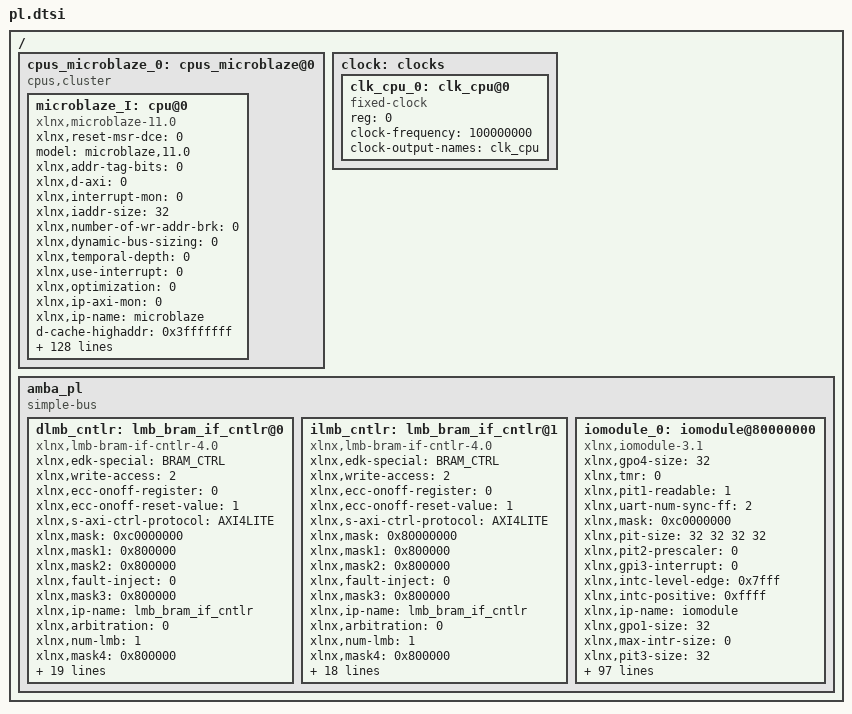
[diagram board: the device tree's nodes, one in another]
/ {
	cpus_microblaze_0: cpus_microblaze@0 {
		#cpu-mask-cells = <1>;
		compatible = "cpus,cluster";
		#address-cells = <1>;
		#size-cells = <0>;
		microblaze_I: cpu@0 {
			xlnx,reset-msr-dce = <0>;
			model = "microblaze,11.0";
			xlnx,addr-tag-bits = <0>;
			xlnx,d-axi = <0>;
			xlnx,interrupt-mon = <0>;
			xlnx,iaddr-size = <32>;
			xlnx,number-of-wr-addr-brk = <0>;
			xlnx,dynamic-bus-sizing = <0>;
			xlnx,temporal-depth = <0>;
			xlnx,use-interrupt = <0>;
			xlnx,optimization = <0>;
			xlnx,ip-axi-mon = <0>;
			xlnx,ip-name = "microblaze";
			d-cache-highaddr = <0x3fffffff>;
			xlnx,dcache-force-tag-lutram = <0>;
			xlnx,pc-width = <17>;
			xlnx,interrupt-is-edge = <0>;
			reg = <0x0>;
			xlnx,async-interrupt = <1>;
			xlnx,use-mmu = <0>;
			xlnx,reset-msr-ee = <0>;
			xlnx,icache-victims = <0>;
			xlnx,use-reorder-instr = <0>;
			xlnx,d-lmb-mon = <0>;
			xlnx,d-lmb-protocol = <0>;
			xlnx,ill-opcode-exception = <0>;
			xlnx,dcache-always-used = <1>;
			xlnx,use-div = <0>;
			xlnx,dc-axi-mon = <0>;
			xlnx,debug-trace-async-reset = <0>;
			xlnx,trace = <0>;
			xlnx,part = "xc7a50tcsg324-1";
			i-cache-baseaddr = <0x0>;
			xlnx,use-config-reset = <0>;
			xlnx,pvr = <0>;
			xlnx,i-lmb-mon = <0>;
			xlnx,dcache-byte-size = <8192>;
			xlnx,fault-tolerant = <0>;
			xlnx,family = "artix7";
			compatible = "xlnx,microblaze-11.0" , "xlnx,microblaze";
			xlnx,data-size = <32>;
			xlnx,mmu-zones = <16>;
			xlnx,debug-trace-size = <8192>;
			xlnx,mmu-privileged-instr = <0>;
			xlnx,enable-discrete-ports = <0>;
			d-cache-line-size = <16>;
			xlnx,d-lmb = <1>;
			xlnx,sco = <0>;
			xlnx,reset-msr-eip = <0>;
			xlnx,debug-interface = <0>;
			clock-frequency = <100000000>;
			xlnx,use-ext-brk = <0>;
			xlnx,daddr-size = <32>;
			xlnx,debug-enabled = <0>;
			xlnx,reset-msr-ice = <0>;
			xlnx,num-sync-ff-dbg-trace-clk = <2>;
			xlnx,i-lmb-protocol = <0>;
			xlnx,endianness = <1>;
			xlnx,fsl-exception = <0>;
			i-cache-line-size = <16>;
			xlnx,use-extended-fsl-instr = <0>;
			xlnx,reset-msr = <0x0>;
			xlnx,dp-axi-mon = <0>;
			device_type = "cpu";
			xlnx,branch-target-cache-size = <0>;
			xlnx,dcache-use-writeback = <0>;
			xlnx,div-zero-exception = <0>;
			xlnx,mmu-tlb-access = <3>;
			bus-handle = <&amba_pl>;
			xlnx,cache-byte-size = <8192>;
			xlnx,pvr-user2 = <0x0>;
			xlnx,opcode-0x0-illegal = <0>;
			xlnx,icache-line-len = <4>;
			xlnx,ecc-use-ce-exception = <0>;
			xlnx,base-vectors = <0x0>;
			xlnx,edk-special = "microblaze";
			xlnx,use-dcache = <0>;
			xlnx,use-barrel = <0>;
			xlnx,reset-msr-bip = <0>;
			xlnx,allow-dcache-wr = <1>;
			xlnx,addr-size = <32>;
			xlnx,debug-external-trace = <0>;
			xlnx,piaddr-size = <32>;
			i-cache-highaddr = <0x3fffffff>;
			xlnx,num-sync-ff-clk-debug = <2>;
			xlnx,debug-event-counters = <5>;
			xlnx,fpu-exception = <0>;
			xlnx,allow-icache-wr = <1>;
			xlnx,g-use-exceptions = <0>;
			xlnx,i-axi = <0>;
			xlnx,g-template-list = <0>;
			xlnx,icache-streams = <0>;
			xlnx,dcache-line-len = <4>;
			xlnx,num-sync-ff-clk = <2>;
			xlnx,edk-iptype = "PROCESSOR";
			xlnx,use-stack-protection = <0>;
			xlnx,use-hw-mul = <0>;
			xlnx,num-sync-ff-dbg-clk = <1>;
			xlnx,interconnect = <2>;
			xlnx,debug-latency-counters = <1>;
			i-cache-size = <8192>;
			xlnx,exceptions-in-delay-slots = <1>;
			xlnx,use-fpu = <0>;
			xlnx,reset-msr-ie = <0>;
			xlnx,edge-is-positive = <1>;
			xlnx,use-pcmp-instr = <0>;
			xlnx,use-icache = <0>;
			d-cache-size = <8192>;
			xlnx,memory-ip-list = "ilmb_cntlr_memory" , "dlmb_cntlr_memory";
			xlnx,async-wakeup = <3>;
			xlnx,use-non-secure = <0>;
			xlnx,dcache-addr-tag = <0>;
			xlnx,number-of-rd-addr-brk = <0>;
			d-cache-baseaddr = <0x0>;
			xlnx,area-optimized = <1>;
			xlnx,avoid-primitives = <0>;
			xlnx,lockstep-slave = <0>;
			xlnx,use-ext-nm-brk = <0>;
			xlnx,instr-size = <32>;
			xlnx,icache-always-used = <1>;
			xlnx,i-lmb = <1>;
			xlnx,mmu-dtlb-size = <4>;
			xlnx,lockstep-select = <0>;
			xlnx,lmb-data-size = <32>;
			xlnx,ic-axi-mon = <0>;
			xlnx,enable-conversion = <1>;
			xlnx,num-sync-ff-clk-irq = <1>;
			xlnx,fsl-links = <0>;
			timebase-frequency = <100000000>;
			xlnx,icache-force-tag-lutram = <0>;
			xlnx,dcache-data-width = <0>;
			xlnx,dcache-victims = <0>;
			xlnx,use-branch-target-cache = <0>;
			xlnx,debug-profile-size = <0>;
			xlnx,unaligned-exceptions = <0>;
			xlnx,lockstep-master = <0>;
			xlnx,freq = <100000000>;
			xlnx,number-of-pc-brk = <1>;
			xlnx,mmu-itlb-size = <2>;
			xlnx,imprecise-exceptions = <0>;
			xlnx,use-msr-instr = <0>;
			xlnx,icache-data-width = <0>;
			xlnx,debug-counter-width = <32>;
		};
	};
	clock: clocks {
		#address-cells = <1>;
		#size-cells = <0>;
		clk_cpu_0: clk_cpu@0 {
			compatible = "fixed-clock";
			reg = <0>;
			clock-frequency = <100000000>;
			clock-output-names = "clk_cpu";
			#clock-cells = <0>;
		};
	};
	amba_pl: amba_pl {
		ranges;
		compatible = "simple-bus";
		#address-cells = <1>;
		#size-cells = <1>;
		dlmb_cntlr: lmb_bram_if_cntlr@0 {
			xlnx,edk-special = "BRAM_CTRL";
			xlnx,write-access = <2>;
			compatible = "xlnx,lmb-bram-if-cntlr-4.0" , "xlnx,axi-bram-ctrl";
			xlnx,ecc-onoff-register = <0>;
			xlnx,ecc-onoff-reset-value = <1>;
			xlnx,s-axi-ctrl-protocol = "AXI4LITE";
			xlnx,mask = <0xc0000000>;
			xlnx,mask1 = <0x800000>;
			xlnx,mask2 = <0x800000>;
			xlnx,fault-inject = <0>;
			xlnx,mask3 = <0x800000>;
			xlnx,ip-name = "lmb_bram_if_cntlr";
			xlnx,arbitration = <0>;
			xlnx,num-lmb = <1>;
			xlnx,mask4 = <0x800000>;
			reg = <0x00000000 0x20000>;
			xlnx,s-axi-ctrl-addr-width = <32>;
			xlnx,mask5 = <0x800000>;
			xlnx,ecc-status-registers = <0>;
			xlnx,mask6 = <0x800000>;
			xlnx,lmb-protocol = <0>;
			xlnx,ce-counter-width = <0>;
			xlnx,mask7 = <0x800000>;
			xlnx,ecc = <0>;
			xlnx,edk-iptype = "PERIPHERAL";
			xlnx,lmb-dwidth = <32>;
			xlnx,interconnect = <0>;
			xlnx,ce-failing-registers = <0>;
			xlnx,ue-failing-registers = <0>;
			status = "okay";
			xlnx,data-width = <32>;
			xlnx,s-axi-ctrl-data-width = <32>;
			xlnx,bram-awidth = <32>;
			xlnx,lmb-awidth = <32>;
			xlnx,name = "dlmb_cntlr";
		};
		ilmb_cntlr: lmb_bram_if_cntlr@1 {
			xlnx,edk-special = "BRAM_CTRL";
			xlnx,write-access = <2>;
			compatible = "xlnx,lmb-bram-if-cntlr-4.0" , "xlnx,axi-bram-ctrl";
			xlnx,ecc-onoff-register = <0>;
			xlnx,ecc-onoff-reset-value = <1>;
			xlnx,s-axi-ctrl-protocol = "AXI4LITE";
			xlnx,mask = <0x80000000>;
			xlnx,mask1 = <0x800000>;
			xlnx,mask2 = <0x800000>;
			xlnx,fault-inject = <0>;
			xlnx,mask3 = <0x800000>;
			xlnx,ip-name = "lmb_bram_if_cntlr";
			xlnx,arbitration = <0>;
			xlnx,num-lmb = <1>;
			xlnx,mask4 = <0x800000>;
			reg = <0x00000000 0x20000>;
			xlnx,s-axi-ctrl-addr-width = <32>;
			xlnx,mask5 = <0x800000>;
			xlnx,ecc-status-registers = <0>;
			xlnx,mask6 = <0x800000>;
			xlnx,lmb-protocol = <0>;
			xlnx,ce-counter-width = <0>;
			xlnx,mask7 = <0x800000>;
			xlnx,ecc = <0>;
			xlnx,edk-iptype = "PERIPHERAL";
			xlnx,lmb-dwidth = <32>;
			xlnx,interconnect = <0>;
			xlnx,ce-failing-registers = <0>;
			xlnx,ue-failing-registers = <0>;
			status = "okay";
			xlnx,s-axi-ctrl-data-width = <32>;
			xlnx,bram-awidth = <32>;
			xlnx,lmb-awidth = <32>;
			xlnx,name = "ilmb_cntlr";
		};
		iomodule_0: iomodule@80000000 {
			xlnx,gpo4-size = <32>;
			xlnx,tmr = <0>;
			xlnx,pit1-readable = <1>;
			xlnx,uart-num-sync-ff = <2>;
			xlnx,mask = <0xc0000000>;
			xlnx,pit-size = < 32 32 32 32 >;
			xlnx,pit2-prescaler = <0>;
			xlnx,gpi3-interrupt = <0>;
			xlnx,intc-level-edge = <0x7fff>;
			xlnx,intc-positive = <0xffff>;
			xlnx,ip-name = "iomodule";
			xlnx,gpo1-size = <32>;
			xlnx,max-intr-size = <0>;
			xlnx,pit3-size = <32>;
			xlnx,fit3-interrupt = <0>;
			reg = <0x80000000 0x10000 0xc0000000 0x40000000>;
			xlnx,fit1-no-clocks = <6216>;
			xlnx,gpi2-size = <32>;
			xlnx,pit2-readable = <1>;
			xlnx,intc-irq-connection = <0>;
			xlnx,uart-tx-interrupt = <0>;
			xlnx,use-config-reset = <0>;
			xlnx,pit2-interrupt = <0>;
			xlnx,intc-base-vectors = <0x0>;
			compatible = "xlnx,iomodule-3.1";
			xlnx,gpo4-init = <0x0>;
			xlnx,pit3-readable = <1>;
			xlnx,pit3-prescaler = <0>;
			xlnx,gpi4-interrupt = <0>;
			xlnx,gpo1-init = <0x0>;
			xlnx,use-io-bus = <1>;
			xlnx,use-gpo1 = <0>;
			xlnx,uart-baudrate = <9600>;
			xlnx,fit4-interrupt = <0>;
			xlnx,gpo3-size = <32>;
			xlnx,use-gpo2 = <0>;
			xlnx,uart-data-bits = <8>;
			xlnx,lmb-protocol = <0>;
			xlnx,pit-prescaler = < 0 0 0 0 >;
			xlnx,gpio1-board-interface = "Custom";
			xlnx,use-gpo3 = <0>;
			xlnx,fit2-no-clocks = <6216>;
			xlnx,options = <1>;
			xlnx,gpio2-board-interface = "Custom";
			xlnx,use-gpo4 = <0>;
			xlnx,gpi4-size = <32>;
			xlnx,gpio3-board-interface = "Custom";
			xlnx,uart-rx-interrupt = <0>;
			xlnx,uart-error-interrupt = <0>;
			xlnx,gpio4-board-interface = "Custom";
			xlnx,pit4-readable = <1>;
			status = "okay";
			xlnx,intc-use-irq-out = <1>;
			xlnx,clock-freq = <100000000>;
			xlnx,gpo-init = < 0 0 0 0 >;
			xlnx,pit2-size = <32>;
			xlnx,intc-intr-size = <1>;
			xlnx,intc-use-ext-intr = <0>;
			xlnx,name = "iomodule_0";
			xlnx,gpi1-size = <32>;
			xlnx,pit3-interrupt = <0>;
			xlnx,intc-has-fast = <1>;
			xlnx,pit-used = < 0 0 0 0 >;
			xlnx,use-gpi1 = <0>;
			xlnx,gpi1-interrupt = <0>;
			xlnx,use-gpi2 = <0>;
			xlnx,use-gpi3 = <0>;
			xlnx,use-gpi4 = <0>;
			xlnx,fit1-interrupt = <0>;
			xlnx,uart-async = <0>;
			xlnx,pit4-prescaler = <0>;
			xlnx,gpo3-init = <0x0>;
			xlnx,intc-addr-width = <17>;
			xlnx,edk-iptype = "PERIPHERAL";
			xlnx,fit3-no-clocks = <6216>;
			xlnx,use-uart-rx = <0>;
			xlnx,pit-mask = <0xFFFFFFFF 0xFFFFFFFF 0xFFFFFFFF 0xFFFFFFFF>;
			xlnx,uart-prog-baudrate = <0>;
			xlnx,uart-freq = <100000000>;
			xlnx,use-pit1 = <0>;
			xlnx,gpo2-size = <32>;
			xlnx,use-pit2 = <0>;
			xlnx,pit4-size = <32>;
			xlnx,pit-readable = < 1 1 1 1 >;
			xlnx,use-pit3 = <0>;
			xlnx,use-pit4 = <0>;
			xlnx,pit4-interrupt = <0>;
			xlnx,gpi3-size = <32>;
			xlnx,intc-async-intr = <0xffff>;
			xlnx,pit1-prescaler = <0>;
			xlnx,avoid-primitives = <0>;
			xlnx,gpi2-interrupt = <0>;
			xlnx,io-bus-error-signals = <0>;
			xlnx,use-tmr-disable = <0>;
			xlnx,use-fit1 = <0>;
			xlnx,pit1-size = <32>;
			xlnx,intc-num-sync-ff = <2>;
			xlnx,uart-board-interface = "Custom";
			xlnx,use-fit2 = <0>;
			xlnx,fit2-interrupt = <0>;
			xlnx,use-fit3 = <0>;
			xlnx,use-fit4 = <0>;
			xlnx,uart-use-parity = <0>;
			xlnx,lmb-dwidth = <32>;
			xlnx,fit4-no-clocks = <6216>;
			xlnx,uart-odd-parity = <0>;
			xlnx,freq = <100000000>;
			xlnx,use-uart-tx = <0>;
			xlnx,pit1-interrupt = <0>;
			xlnx,gpo2-init = <0x0>;
			xlnx,io-mask = <0xc0000000>;
			xlnx,lmb-awidth = <32>;
		};
	};
};
